# D1H.pdf register map
Vendor: Allwinner; Series: D1H.pdf; File version: 0.1
CPU: XuanTie C906 RISC-V CPU 0, little endian, MPU, FPU, double-precision FPU, 0 interrupt priority bits
Registers are 32-bit, read-write, reset 0x0 unless marked. A register's access mark holds for its fields unless they carry their own. Offsets are from the block's base; [hi:lo] are bit positions; {n}, {i} and the like mark numbered series.

## CE_NS
Base 0x03040000
0x00 CE_TDA — Task Descriptor Address
  [31:0] TASK — Task Descriptor Address Configure as the first address of the descriptor structure.
0x08 CE_ICR — Interrupt Control Register
  [3:0] TASK — Task Channel3–0 Interrupt Enable 0: Disable 1: Enable
0x0C CE_ISR — Interrupt Status Register
  [3:0] TASK write-1-clears — Task Channel3–0 End Pending 0: Not finished 1: Finished It indicates whether task is completed. Write the corresponding channel bit of the register to clear the end flag. When the last task in the task chain ends, the operation of the task chain will end normally. If the task fails in the middle, the task chain will be aborted. The CE_ISR register will be automatically updated when it ends normally or aborts abnormally. And it is determined whether to generate an interrupt signal according to the IE configuration (bit31) of when the current task ends or aborts. If using interrupt, after receiving the interrupt, read the corresponding channel bit of CE_ISR to judge whether it ends successfully or stops failure. If not using interrupt, the CE_ISR status register can be continuously queried for the channel bit until the successful end flag is set or the failure stop flag is set. Write the corresponding channel bit of the register to clear the end flag. If it fails to stop, you can read the error code on the channel corresponding to the register.
0x10 CE_TLR — Task Load Register
  [0] TASK — Task Load When set, the CE can load the descriptor of task if the task FIFO is not full.
0x14 CE_TSR — Task Status Register
  [1:0] RUNNING_CHANNEL ro — Running Channel Number 00: Task channel0 01: Task channel1 10: Task channel2 11: Task channel3
    {v}=Task_channel{v} (v=0..3)
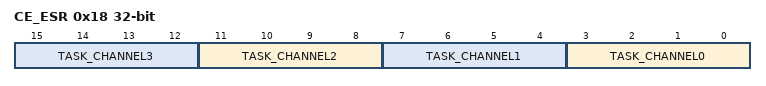
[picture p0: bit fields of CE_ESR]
0x18 CE_ESR — Error Status Register
  [4n+3:4n] TASK_CHANNEL{n} write-1-clears (n=0..3) — Task Channel{n} Error Type xxx1: Algorithm not support xx1x: Data length error x1xx: keysram access error for AES 1xxx: Reserved
0x24 CE_CSA — DMA Current Source Address
  [31:0] CUR_SRC_ADDR ro — Current source address
0x28 CE_CDA — DMA Current Destination Address
  [31:0] CUR_DST_ADDR ro — Current destination address
0x2C CE_TPR — Throughput Register
  [31:0] TP_NUM write-clears — It indicates the throughput writing to this register at last time. Writing to this register will clear it to 0. The Security ID (SID) is used to program and read keys which include chip ID, thermal sensor, HASH code, and so on. The SID module has the following features: 2 Kbits electrical fuse (eFuse) Backup eFuse information by using SID_SRAM A fuse only can program one time Burning the key to the SID Reading the key use status in the SID Loading the key to the CE

## RISCV_CFG
Base 0x06010000
0x04 RISCV_STA_ADD0_REG — RISCV Start Address0 Register
  [31:0] STA_ADD_L — Start Address Low 32-bit The bit0 is fixed as 0 and can not be written.
0x08 RISCV_STA_ADD1_REG — RISCV Start Address1 Register
  [7:0] STA_ADD_H — Start Address High 8-bit.
0x10 RF1P_CFG_REG reset 0x13 — RF1P Configuration Register
  [7:0] RF1P_CFG — RF1P Configuration
0x1C ROM_CFG_REG reset 0x2 — ROM Configuration Register
  [7:0] ROM_CFG — ROM Configuration
0x20 WAKEUP_EN_REG — Wakeup Enable Register
  [0] WP_EN — Wakeup Enable
{0x24+4i} WAKEUP_MASK{i}_REG (i=0..4) — Wakeup Mask{i} Register
  [31:0] WP_MASK{i} — Wakeup Mask{i}
0x40 TS_TMODE_SEL_REG — Timestamp Test Mode Select Register
  [0] TS_TEST_MODE_EN — Timestamp Test Mode Enable 0: Normal Mode 1: Test Mode
    0=Normal Mode; 1=Test Mode
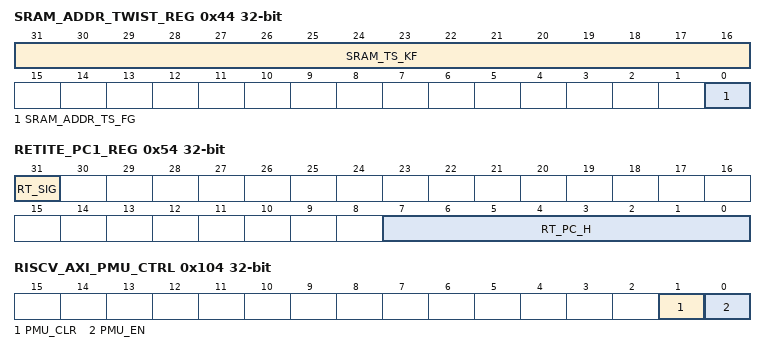
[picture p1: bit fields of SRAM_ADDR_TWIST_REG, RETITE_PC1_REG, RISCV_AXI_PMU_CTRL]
0x44 SRAM_ADDR_TWIST_REG (reset mask 0x1) — SRAM Address Twist Register
  [31:16] SRAM_TS_KF wo — SRAM Twist Keyfield The bit 0 can be written only if this key field is written by 0x16AA.
  [0] SRAM_ADDR_TS_FG — SRAM Address Twist Flag. When this bit is set up, the RISCV_BROM area would become invisible, and the start address of SRAM A1 would be twisted into 0x0, the original start address of SRAM A1 is 0x0002 0000. After the address has been twisted, RISCV reads data from 0x0002000 to 0x0002ffff as same as from 0x0 to 0xffff.
0x48 WORK_MODE_REG — Work Mode Register
  [1:0] WM_STA ro — Work Mode Status 00: Normal Mode 01: Low Power Mode 10: Debug Mode 11: Reserved
    0=Normal Mode; 1=Low (Low Power Mode); 2=Debug Mode
0x50 RETITE_PC0_REG — Retire PC0 Register
  [31:0] RT_PC_L ro — Retire PC[31:0] It indicates the current retiring instruction PC[31:0].
0x54 RETITE_PC1_REG — Retire PC1 Register
  [31] RT_SIG ro — Retire Signal 0: The current period has not the retired instruction 1: The current period has the retired instruction
    0=current_period_has_not_the_retired (The current period has not the retired instruction); 1=current_period_has_the_retired (The current period has the retired instruction)
  [7:0] RT_PC_H ro — Retire PC[39:31] It indicates the current retiring instruction PC[39:31].
{0x60+4i} IRQ_MODE{i}_REG (i=0..4) — IRQ Mode{i} Register
  [31:0] IRQ_MD{i} — IRQ Mode{i} 0: High-level trigger 1: Rising edge trigger
0x104 RISCV_AXI_PMU_CTRL — RISCV AXI PMU Control Register
  [1] PMU_CLR wo write-clears — PMU Clear 0: No operation 1: PMU cleared
    0=No_operation; 1=PMU (PMU cleared)
  [0] PMU_EN — PMU Enable 0: PMU disabled 1: PMU enabled
    0=PMU_disabled; 1=PMU_enabled
0x108 RISCV_AXI_PMU_PRD — RISCV AXI PMU Period Register
  [31:0] PRD — Monitor period Suggest that the field is in units of 1 us (1 ms).
0x10C RISCV_AXI_PMU_LAT_RD — RISCV AXI PMU Read Latency Register
  [31:0] LAT_RD ro — Monitor the total latency of read-channel durning period
0x110 RISCV_AXI_PMU_LAT_WR — RISCV AXI PMU Write Latency Register
  [31:0] LAT_WR ro — Monitor the total latency of write-channel durning period
0x114 RISCV_AXI_PMU_REQ_RD — RISCV AXI PMU Read Request Register
  [31:0] REQ_RD ro — Monitor the total command numbers of read-channel durning period
0x118 RISCV_AXI_PMU_REQ_WR — RISCV AXI PMU Write Request Register
  [31:0] REQ_WR ro — Monitor the total command numbers of write-channel durning period
0x11C RISCV_AXI_PMU_BW_RD — RISCV AXI PMU Read Bandwidth Register
  [31:0] BW_RD ro — Monitor the total data (KB) of read-channel durning period
0x120 RISCV_AXI_PMU_BW_WR — RISCV AXI PMU Write Bandwidth Register
  [31:0] BW_WR ro — Monitor the total data (KB) of write-channel durning period
